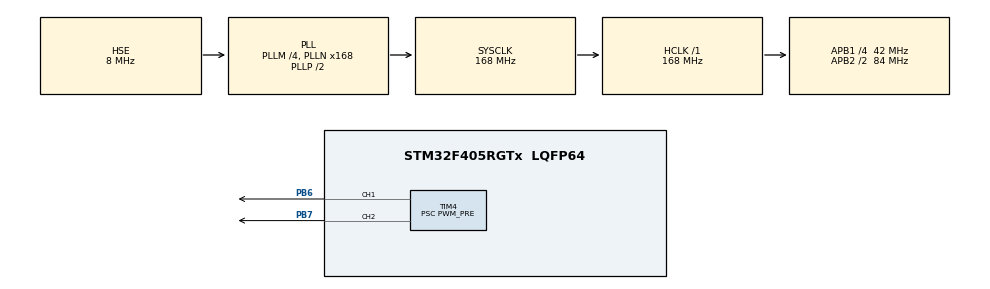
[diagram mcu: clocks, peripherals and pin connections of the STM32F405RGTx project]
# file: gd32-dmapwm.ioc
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Dma.Request0=TIM4_CH1
Dma.Request1=TIM4_CH2
Dma.TIM4_CH1.0.Direction=DMA_MEMORY_TO_PERIPH
Dma.TIM4_CH1.0.FIFOMode=DMA_FIFOMODE_DISABLE
Dma.TIM4_CH1.0.Instance=DMA1_Stream0
Dma.TIM4_CH1.0.MemDataAlignment=DMA_MDATAALIGN_HALFWORD
Dma.TIM4_CH1.0.MemInc=DMA_MINC_ENABLE
Dma.TIM4_CH1.0.Mode=DMA_CIRCULAR
Dma.TIM4_CH1.0.PeriphDataAlignment=DMA_PDATAALIGN_HALFWORD
Dma.TIM4_CH1.0.PeriphInc=DMA_PINC_DISABLE
Dma.TIM4_CH1.0.Priority=DMA_PRIORITY_LOW
Dma.TIM4_CH2.1.Direction=DMA_MEMORY_TO_PERIPH
Dma.TIM4_CH2.1.FIFOMode=DMA_FIFOMODE_DISABLE
Dma.TIM4_CH2.1.Instance=DMA1_Stream3
Dma.TIM4_CH2.1.MemDataAlignment=DMA_MDATAALIGN_HALFWORD
Dma.TIM4_CH2.1.MemInc=DMA_MINC_ENABLE
Dma.TIM4_CH2.1.Mode=DMA_CIRCULAR
Dma.TIM4_CH2.1.PeriphDataAlignment=DMA_PDATAALIGN_HALFWORD
Dma.TIM4_CH2.1.PeriphInc=DMA_PINC_DISABLE
Dma.TIM4_CH2.1.Priority=DMA_PRIORITY_LOW
Mcu.Family=STM32F4
Mcu.Name=STM32F405RGTx
Mcu.Package=LQFP64
Mcu.UserConstants=PWM_PRE,839;PWM_CNT,999
NVIC.DMA1_Stream0_IRQn=true\:0\:0\:false\:false\:true\:false\:true
NVIC.DMA1_Stream3_IRQn=true\:0\:0\:false\:false\:true\:false\:true
NVIC.PriorityGroup=NVIC_PRIORITYGROUP_4
PA13.Mode=Serial_Wire
PA13.Signal=SYS_JTMS-SWDIO
PA14.Mode=Serial_Wire
PA14.Signal=SYS_JTCK-SWCLK
PB6.Signal=S_TIM4_CH1
PB7.Signal=S_TIM4_CH2
PH0-OSC_IN.Mode=HSE-External-Oscillator
PH0-OSC_IN.Signal=RCC_OSC_IN
PH1-OSC_OUT.Mode=HSE-External-Oscillator
PH1-OSC_OUT.Signal=RCC_OSC_OUT
ProjectManager.HeapSize=0x200
ProjectManager.StackSize=0x400
ProjectManager.TargetToolchain=STM32CubeIDE
RCC.48MHZClocksFreq_Value=84000000
RCC.AHBFreq_Value=168000000
RCC.APB1CLKDivider=RCC_HCLK_DIV4
RCC.APB1Freq_Value=42000000
RCC.APB1TimFreq_Value=84000000
RCC.APB2CLKDivider=RCC_HCLK_DIV2
RCC.APB2Freq_Value=84000000
RCC.APB2TimFreq_Value=168000000
RCC.CortexFreq_Value=168000000
RCC.HCLKFreq_Value=168000000
RCC.HSE_VALUE=8000000
RCC.HSI_VALUE=16000000
RCC.LSE_VALUE=32768
RCC.PLLM=4
RCC.PLLN=168
RCC.PLLSourceVirtual=RCC_PLLSOURCE_HSE
RCC.SYSCLKFreq_VALUE=168000000
RCC.SYSCLKSource=RCC_SYSCLKSOURCE_PLLCLK
RCC.VCOOutputFreq_Value=336000000
SH.S_TIM4_CH1.0=TIM4_CH1,PWM Generation1 CH1
SH.S_TIM4_CH2.0=TIM4_CH2,PWM Generation2 CH2
TIM4.Channel-PWM\ Generation1\ CH1=TIM_CHANNEL_1
TIM4.Channel-PWM\ Generation2\ CH2=TIM_CHANNEL_2
TIM4.Period=PWM_CNT
TIM4.Prescaler=PWM_PRE
VP_TIM4_VS_ClockSourceINT.Mode=Internal
board=custom

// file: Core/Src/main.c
/* USER CODE BEGIN Header */
/**
  ******************************************************************************
  * @file           : main.c
  * @brief          : Main program body
  ******************************************************************************
  * @attention
  *
  * <h2><center>&copy; Copyright (c) 2021 STMicroelectronics.
  * All rights reserved.</center></h2>
  *
  * This software component is licensed by ST under BSD 3-Clause license,
  * the "License"; You may not use this file except in compliance with the
  * License. You may obtain a copy of the License at:
  *                        opensource.org/licenses/BSD-3-Clause
  *
  ******************************************************************************
  */
/* USER CODE END Header */
#include "main.h"

/* USER CODE BEGIN PD */
#define BUFFER_SIZE 10
/* USER CODE END PD */

TIM_HandleTypeDef htim4;
DMA_HandleTypeDef hdma_tim4_ch1;
DMA_HandleTypeDef hdma_tim4_ch2;

/* USER CODE BEGIN PV */
uint16_t buf1[BUFFER_SIZE * 2] = {0};
uint16_t buf2[BUFFER_SIZE * 2] = {0};
/* USER CODE END PV */

void SystemClock_Config(void);
static void MX_GPIO_Init(void);
static void MX_DMA_Init(void);
static void MX_TIM4_Init(void);

/* USER CODE BEGIN 0 */

void update_buffer(HAL_TIM_ActiveChannel channel, uint16_t *buffer) {

}

// Done sending first half of the DMA buffer - this can now safely be updated
void HAL_TIM_PWM_PulseFinishedHalfCpltCallback(TIM_HandleTypeDef *htim) {

		if (htim->Instance == TIM3) {
			uint16_t *buffer;
                if (htim->Channel == HAL_TIM_ACTIVE_CHANNEL_1) {
                	buffer = buf1[0];
                } else {
                	buffer = buf2[0];
                }
                update_buffer(htim->Channel, buffer);
        }

}

// Done sending the second half of the DMA buffer - this can now be safely updated
void HAL_TIM_PWM_PulseFinishedCallback(TIM_HandleTypeDef *htim) {

		if (htim->Instance == TIM3) {
				uint16_t *buffer;
                if (htim->Channel == HAL_TIM_ACTIVE_CHANNEL_1) {

                } else {

                }
                //update_next_buffer(&dma_buffer[BUFFER_SIZE]);
        }

}

/* USER CODE END 0 */

int main(void)
{

  /* MCU Configuration--------------------------------------------------------*/

  /* Reset of all peripherals, Initializes the Flash interface and the Systick. */
  HAL_Init();

  /* Configure the system clock */
  SystemClock_Config();

  /* Initialize all configured peripherals */
  MX_GPIO_Init();
  MX_DMA_Init();
  MX_TIM4_Init();

  /* Infinite loop */
  while (1)
  {

  }
}

void SystemClock_Config(void)
{
  RCC_OscInitTypeDef RCC_OscInitStruct = {0};
  RCC_ClkInitTypeDef RCC_ClkInitStruct = {0};

  /** Configure the main internal regulator output voltage
  */
  __HAL_RCC_PWR_CLK_ENABLE();
  __HAL_PWR_VOLTAGESCALING_CONFIG(PWR_REGULATOR_VOLTAGE_SCALE1);
  /** Initializes the RCC Oscillators according to the specified parameters
  * in the RCC_OscInitTypeDef structure.
  */
  RCC_OscInitStruct.OscillatorType = RCC_OSCILLATORTYPE_HSE;
  RCC_OscInitStruct.HSEState = RCC_HSE_ON;
  RCC_OscInitStruct.PLL.PLLState = RCC_PLL_ON;
  RCC_OscInitStruct.PLL.PLLSource = RCC_PLLSOURCE_HSE;
  RCC_OscInitStruct.PLL.PLLM = 4;
  RCC_OscInitStruct.PLL.PLLN = 168;
  RCC_OscInitStruct.PLL.PLLP = RCC_PLLP_DIV2;
  RCC_OscInitStruct.PLL.PLLQ = 4;
  if (HAL_RCC_OscConfig(&RCC_OscInitStruct) != HAL_OK)
  {
    Error_Handler();
  }
  /** Initializes the CPU, AHB and APB buses clocks
  */
  RCC_ClkInitStruct.ClockType = RCC_CLOCKTYPE_HCLK|RCC_CLOCKTYPE_SYSCLK
                              |RCC_CLOCKTYPE_PCLK1|RCC_CLOCKTYPE_PCLK2;
  RCC_ClkInitStruct.SYSCLKSource = RCC_SYSCLKSOURCE_PLLCLK;
  RCC_ClkInitStruct.AHBCLKDivider = RCC_SYSCLK_DIV1;
  RCC_ClkInitStruct.APB1CLKDivider = RCC_HCLK_DIV4;
  RCC_ClkInitStruct.APB2CLKDivider = RCC_HCLK_DIV2;

  if (HAL_RCC_ClockConfig(&RCC_ClkInitStruct, FLASH_LATENCY_5) != HAL_OK)
  {
    Error_Handler();
  }
}

static void MX_TIM4_Init(void)
{

  TIM_ClockConfigTypeDef sClockSourceConfig = {0};
  TIM_MasterConfigTypeDef sMasterConfig = {0};
  TIM_OC_InitTypeDef sConfigOC = {0};

  htim4.Instance = TIM4;
  htim4.Init.Prescaler = PWM_PRE;
  htim4.Init.CounterMode = TIM_COUNTERMODE_UP;
  htim4.Init.Period = PWM_CNT;
  htim4.Init.ClockDivision = TIM_CLOCKDIVISION_DIV1;
  htim4.Init.AutoReloadPreload = TIM_AUTORELOAD_PRELOAD_DISABLE;
  if (HAL_TIM_Base_Init(&htim4) != HAL_OK)
  {
    Error_Handler();
  }
  sClockSourceConfig.ClockSource = TIM_CLOCKSOURCE_INTERNAL;
  if (HAL_TIM_ConfigClockSource(&htim4, &sClockSourceConfig) != HAL_OK)
  {
    Error_Handler();
  }
  if (HAL_TIM_PWM_Init(&htim4) != HAL_OK)
  {
    Error_Handler();
  }
  sMasterConfig.MasterOutputTrigger = TIM_TRGO_RESET;
  sMasterConfig.MasterSlaveMode = TIM_MASTERSLAVEMODE_DISABLE;
  if (HAL_TIMEx_MasterConfigSynchronization(&htim4, &sMasterConfig) != HAL_OK)
  {
    Error_Handler();
  }
  sConfigOC.OCMode = TIM_OCMODE_PWM1;
  sConfigOC.Pulse = 0;
  sConfigOC.OCPolarity = TIM_OCPOLARITY_HIGH;
  sConfigOC.OCFastMode = TIM_OCFAST_DISABLE;
  if (HAL_TIM_PWM_ConfigChannel(&htim4, &sConfigOC, TIM_CHANNEL_1) != HAL_OK)
  {
    Error_Handler();
  }
  if (HAL_TIM_PWM_ConfigChannel(&htim4, &sConfigOC, TIM_CHANNEL_2) != HAL_OK)
  {
    Error_Handler();
  }
  HAL_TIM_MspPostInit(&htim4);

}

static void MX_DMA_Init(void)
{

  /* DMA controller clock enable */
  __HAL_RCC_DMA1_CLK_ENABLE();

  /* DMA interrupt init */
  /* DMA1_Stream0_IRQn interrupt configuration */
  HAL_NVIC_SetPriority(DMA1_Stream0_IRQn, 0, 0);
  HAL_NVIC_EnableIRQ(DMA1_Stream0_IRQn);
  /* DMA1_Stream3_IRQn interrupt configuration */
  HAL_NVIC_SetPriority(DMA1_Stream3_IRQn, 0, 0);
  HAL_NVIC_EnableIRQ(DMA1_Stream3_IRQn);

}

static void MX_GPIO_Init(void)
{

  /* GPIO Ports Clock Enable */
  __HAL_RCC_GPIOH_CLK_ENABLE();
  __HAL_RCC_GPIOA_CLK_ENABLE();
  __HAL_RCC_GPIOB_CLK_ENABLE();

}

void Error_Handler(void)
{
  __disable_irq();
  while (1)
  {
  }
}

/************************ (C) COPYRIGHT STMicroelectronics *****END OF FILE****/
